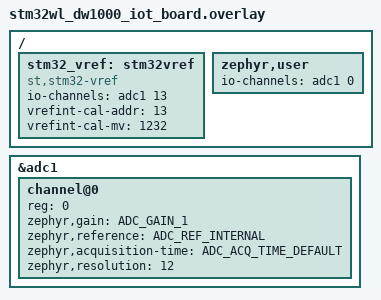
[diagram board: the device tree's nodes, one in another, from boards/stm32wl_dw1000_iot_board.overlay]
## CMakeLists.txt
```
cmake_minimum_required(VERSION 3.20.0)

find_package(Zephyr REQUIRED HINTS $ENV{ZEPHYR_BASE})
add_subdirectory(drivers)

project(stm32wle5_rtos_adc)

zephyr_include_directories(include)

FILE(GLOB app_sources src/*.c)
target_sources(app PRIVATE ${app_sources})
```

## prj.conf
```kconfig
# Debugger Support
CONFIG_UART_CONSOLE=y
CONFIG_CONSOLE=y

# Communication Bus Support
CONFIG_GPIO=y
CONFIG_SPI=y

# Hardware Support
CONFIG_SENSOR=y
CONFIG_ADC=y

# Power Management Support
CONFIG_PM=n
CONFIG_PM_DEVICE=n
CONFIG_PM_DEVICE_RUNTIME=n
CONFIG_PM_DEVICE_RUNTIME_EXCLUSIVE=n

# Flash Memory Support
CONFIG_EEPROM=y
CONFIG_FLASH=y
CONFIG_MPU_ALLOW_FLASH_WRITE=y
```

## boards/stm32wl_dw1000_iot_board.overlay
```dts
/*
 * Copyright (c) 2023
 * Regis Rousseau
 * Univ Lyon, INSA Lyon, Inria, CITI, EA3720
 * SPDX-License-Identifier: Apache-2.0
 */

/* VREF internal voltage monitoring */
/* internal voltage reference of STM32, IN13 - see datasheet pg 42/149 */
/* Vrefint = 1232mV max - see datasheet pg 78/149, table 36 */
/ {
	stm32_vref: stm32vref {
    	compatible = "st,stm32-vref";
		io-channels = <&adc1 13>;
		vrefint-cal-addr = <13>;
		vrefint-cal-mv = <1232>;
    	status = "okay";
	};
};

/* configuration of ADC for geophone sensor */
/* adjust channel number according to pinmux in board.dts */
/* PB13 ADC_GSONE -> ADC_IN0, see datasheet Pinout Config pg 57/149 */
/ {
	zephyr,user {		
		io-channels = <&adc1 0>;
	};
};

/* channel IN0 configuration */
&adc1 {
	#address-cells = <1>;
	#size-cells = <0>;
	channel@0 {
		reg = <0>;
		zephyr,gain = "ADC_GAIN_1";
		zephyr,reference = "ADC_REF_INTERNAL";
		zephyr,acquisition-time = <ADC_ACQ_TIME_DEFAULT>;
		zephyr,resolution = <12>;
	};
};
```

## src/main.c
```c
/*
 * Copyright (c) 2023
 * Regis Rousseau
 * Univ Lyon, INSA Lyon, Inria, CITI, EA3720
 * SPDX-License-Identifier: Apache-2.0
 */
 
#include "app_adc.h"
#include "app_vref.h"
#include "app_rom.h"


//  ======== interrupt sub-routine ===============================
void geo_work_handler(struct k_work *work_geo)
{
	const struct device *rom_dev = NULL;

	printk("ADC handler called\n");
	app_rom_handler(rom_dev);
}
K_WORK_DEFINE(geo_work, geo_work_handler);

void geo_timer_handler(struct k_timer *geo_dum)
{
	k_work_submit(&geo_work);
}
K_TIMER_DEFINE(geo_timer, geo_timer_handler, NULL);

//  ======== main ===============================================
int8_t main(void)
{
	const struct device *rom_dev = NULL;
	const struct device *vref_dev = NULL;
	uint16_t vref;

	// setup all devices
	app_rom_init(rom_dev);
	app_stm32_vref_init(vref_dev);

	printk("ADC STM32 Example\nBoard: %s\n", CONFIG_BOARD);

	// beginning of interrupt subroutine
//	k_timer_start(&geo_timer, K_NO_WAIT, K_MSEC(5000));
	vref_dev = DEVICE_DT_GET_ONE(st_stm32_vref);
	vref = app_stm32_get_vref(vref_dev);

	while(1) {
		uint16_t val = app_adc_get_val(vref);
		k_sleep(K_MSEC(1000)); // for the test
	}
	return 0;
}
```

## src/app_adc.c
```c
/*
 * Copyright (c) 2023
 * Regis Rousseau
 * Univ Lyon, INSA Lyon, Inria, CITI, EA3720
 * SPDX-License-Identifier: Apache-2.0
 */

#include "app_adc.h"
#include "app_vref.h"

//  ======== globals ============================================
uint16_t sp_buf;		

static const struct adc_dt_spec adc_channels[] = {
	DT_FOREACH_PROP_ELEM(DT_PATH(zephyr_user), io_channels, DT_SPEC_AND_COMMA)
};

struct adc_sequence adc_ch0_seq = {
	.buffer 		= &sp_buf,
	.buffer_size	= sizeof(sp_buf),
	.calibrate 		= true,
};

//  ======== app_adc_get_val ====================================
uint16_t app_adc_get_val(uint16_t val)
{
	int8_t err;
	uint16_t val_mv, buf;

	// getting STM32 ADC device at GPIO IN0 PB13
	for (size_t i = 0U; i < ARRAY_SIZE(adc_channels); i++) {
		if (!device_is_ready(adc_channels[i].dev)) {
			printk("ADC controller device %s not ready\n", adc_channels[i].dev->name);
		return 0;
		}
		
		// getting channel setup in devicetree
		err = adc_channel_setup_dt(&adc_channels[i]);
		if (err < 0) {
			printk("could not setup channel 0. error: %d\n", err);
			return 0;
		}
	}

	for (size_t i = 0U; i < ARRAY_SIZE(adc_channels); i++) {
		// initialization of channel and getting data
		(void)adc_sequence_init_dt(&adc_channels[i], &adc_ch0_seq);

		// getting value and printing numerical data
		// resolution 12 bits: 0 to 4095 (uint16)
		(void)adc_read(adc_channels[i].dev, &adc_ch0_seq);
		buf = (sp_buf*val)/4096;
		val_mv = (sp_buf*val)/3300;
		printk("buffer: %"PRIu16", adc num: %"PRIu16" - adc mv: %"PRIu16"\n", sp_buf, buf, val_mv);
	}
	return buf;
}
```

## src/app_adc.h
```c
/*
 * Copyright (c) 2023
 * Regis Rousseau
 * Univ Lyon, INSA Lyon, Inria, CITI, EA3720
 * SPDX-License-Identifier: Apache-2.0
 */

#ifndef APP_ADC_H
#define APP_ADC_H

//  ======== includes =============================================
#include <zephyr/kernel.h>
#include <zephyr/device.h>
#include <zephyr/drivers/adc.h>
#include <zephyr/drivers/sensor.h>

//  ======== defines ==============================================
#define DT_SPEC_AND_COMMA(node_id, prop, idx)   ADC_DT_SPEC_GET_BY_IDX(node_id, idx)

//  ======== prototypes ===========================================
uint16_t app_adc_get_val(uint16_t val);

#endif /* APP_ADC_H */
```

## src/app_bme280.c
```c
/*
 * Copyright (c) 2023
 * Regis Rousseau
 * Univ Lyon, INSA Lyon, Inria, CITI, EA3720
 * SPDX-License-Identifier: Apache-2.0
 */

 #include "app_bme280.h"
 #include "app_nvs.h"

int8_t app_bme280_init(const struct device *dev)
{
    dev = DEVICE_DT_GET_ANY(bosch_bme280);
    if (dev == NULL) {
        printk("error: no bme280 device found\n");
		return 0;
	}

    if (!device_is_ready(dev)) {
		printk("error: bme280 is not ready\n");
		return 0;
	}

    printk("found device \"%s\", getting bme280 data\n", dev->name);
    return 0;
}

int8_t app_bme280_handler(const struct device *dev)
{
    static struct nvs_fs fs;
    struct sensor_value temp;
    struct sensor_value hum;
    int8_t ret = 0;

    dev = DEVICE_DT_GET_ANY(bosch_bme280);

	ret = sensor_sample_fetch(dev);
    if (ret < 0 && ret != -EBADMSG) { 
	    printk("bme280 device sample is not up to date. error: %d\n", ret);
	    return 0;
    }

	ret = sensor_channel_get(dev, SENSOR_CHAN_AMBIENT_TEMP, &temp);
    if (ret < 0) {
        printk("can't read sensor channels. error: %d\n", ret);
	    return 0;
    }
    nvs_write(&fs, BME280_TEMP_ID, &temp, sizeof(temp));

	ret = sensor_channel_get(dev, SENSOR_CHAN_HUMIDITY, &hum);
    if (ret < 0) {
        printk("can't read sensor channels. error: %d\n");
	    return 0;
    }

    nvs_write(&fs, BME280_HUM_ID, &hum, sizeof(hum));
    printk("temp: %d.%03d; press: %d.%03d\n",temp.val1, temp.val2, hum.val1, hum.val2);

    return 0;
}
```

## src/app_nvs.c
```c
/*
 * Copyright (c) 2023
 * Regis Rousseau
 * Univ Lyon, INSA Lyon, Inria, CITI, EA3720
 * SPDX-License-Identifier: Apache-2.0
 */

#include "app_nvs.h"

int app_nvs_init(struct nvs_fs *fs)
{
	struct flash_pages_info info;
	int ret = 0;

	fs->flash_device = NVS_PARTITION_DEVICE;
	if (!device_is_ready(fs->flash_device)) {
		printk("flash device %s is not ready\n", fs->flash_device->name);
		return 0;
	}

	fs->offset = NVS_PARTITION_OFFSET;
	ret = flash_get_page_info_by_offs(fs->flash_device, fs->offset, &info);
	if (ret) {
		printk("unable to get page info. error: %d\n", ret);
		return 0;
	}

	fs->sector_size = info.size;
	if (!fs->sector_size || fs->sector_size % info.size) {
		printk("invalid sector size");
		return -EINVAL;
	}

	fs->sector_count = 2U;

	ret = nvs_mount(fs);
	if (ret) {
		printk("flash init failed. error: %d\n", ret);
		return 0;
	}
}
```

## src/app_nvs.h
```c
/*
 * Copyright (c) 2023
 * Regis Rousseau
 * Univ Lyon, INSA Lyon, Inria, CITI, EA3720
 * SPDX-License-Identifier: Apache-2.0
 */

#ifndef APP_NVS_H
#define APP_NVS_H

#include <zephyr/kernel.h>
#include <zephyr/device.h>

#include <zephyr/fs/nvs.h>
#include <zephyr/drivers/flash.h>
#include <zephyr/storage/flash_map.h>

#define NVS_PARTITION			storage_partition
#define NVS_PARTITION_DEVICE	FIXED_PARTITION_DEVICE(NVS_PARTITION)
#define NVS_PARTITION_OFFSET	FIXED_PARTITION_OFFSET(NVS_PARTITION)

#define TIMER_RTC_ID            1
#define STM32_VBAT_ID           2
#define BME280_TEMP_ID          3
#define BME280_HUM_ID           4

int app_nvs_init(struct nvs_fs *fs);

#endif /* APP_NVS_H */
```

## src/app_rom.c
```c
/*
 * Copyright (c) 2023
 * Regis Rousseau
 * Univ Lyon, INSA Lyon, Inria, CITI, EA3720
 * SPDX-License-Identifier: Apache-2.0
 */

#include "app_rom.h"

//  ======== globals ============================================
int8_t ind;		// index used by Interrupt Service Routine

//  ======== app_rom_init =========================================
int8_t app_rom_init(const struct device *dev)
{
	int8_t ret;
	ssize_t size, page;

	// getting eeprom device
	dev = DEVICE_DT_GET(DT_ALIAS(eeprom0));

    if (dev == NULL) {
		printk("no eeprom device found. error: %d\n", dev);
		return 0;
	}
	
	if (!device_is_ready(dev)) {
		printk("eeprom is not ready\n");
		return 0;
	} else {
        printk("- found device \"%s\", writing/reading data\n", dev->name);
    }

	// getting the size of eeprom in bytes
	size = eeprom_get_size(dev);
	printk("size of eeprom: %zu\n", size);

	// getting the total number of flash pages in bytes
	page = flash_get_page_count(dev);
	printk("number of pages: %zu\n", page);

	// erasing all page at @0x00
	ret  = flash_erase(dev, ROM_OFFSET, 1024*ROM_PAGE_SIZE);
	if (ret!=0) {
		printk("error erasing flash. error: %d\n", ret);
	} else {
		printk("erased all %zu pages\n", page);
	}
	
	// initialisation of isr index
	ind = 0;
	return 0;
}

//  ======== app_rom_write ========================================
int8_t app_rom_write(const struct device *dev, uint16_t data[])
{
	int8_t ret;
	
	// writing data in the first page of 2kbytes
	ret = flash_write(dev, ROM_OFFSET, &data, sizeof(data));

	if (ret!=0) {
		printk("error writing data. error: %d\n", ret);
	} else {
		printk("wrote %zu bytes to address 0x00\n", sizeof(data));
	}

	// printing data
	for (ind = 0; ind < ROM_MAX_RECORDS; ind++) {
		printk("wrt -> rom val: %"PRIu16"\n", data[ind]);
	}
	return 0;
}

//  ======== app_rom_read =========================================
int8_t app_rom_read(const struct device *dev)
{
	int8_t ret;
	uint16_t data[ROM_MAX_RECORDS];

	// reading the first page
	ret = flash_read(dev, ROM_OFFSET, &data, sizeof(data));
	if (ret) {
		printk("error reading data. error: %d\n", ret);
	} else {
		printk("read %zu bytes from address 0x00\n", sizeof(data));
	}

	// reading data
	for (ind = 0; ind < ROM_MAX_RECORDS; ind++) {
		printk("rd -> rom val: %"PRIu16"\n", data[ind]);
	}
	return 0;
}

//  ======== app_rom_handler =======================================
int8_t app_rom_handler(const struct device *dev)
{
	int8_t ret;
	uint16_t data[ROM_MAX_RECORDS];

	// getting eeprom device
	dev = DEVICE_DT_GET(DT_ALIAS(eeprom0));

	// putting n structures in fisrt page for this test
	while (ind < ROM_MAX_RECORDS) {
		data[ind] = app_adc_get_val();
		ind++;
	}

	// writing and reading stored data
	app_rom_write(dev, data);
	app_rom_read(dev);

	// cleaning data storage partition
	(void)flash_erase(dev, ROM_OFFSET, 1024*ROM_PAGE_SIZE);
	ind = 0;
	return 0;
}
```

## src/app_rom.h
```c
/*
 * Copyright (c) 2023
 * Regis Rousseau
 * Univ Lyon, INSA Lyon, Inria, CITI, EA3720
 * SPDX-License-Identifier: Apache-2.0
 */
 
#ifndef APP_ROM_H_
#define APP_ROM_H_

//  ======== includes =============================================
#include <zephyr/kernel.h>
#include <zephyr/device.h>
#include <zephyr/drivers/flash.h>
#include <zephyr/drivers/eeprom.h>

//  ======== defines ==============================================
#define ROM_OFFSET              0x00
#define ROM_PAGE_SIZE           512
#define ROM_MAX_RECORDS         3   // 1 structure: ID+value = 3 bytes
                                    // number of structures to store per page
                                            
//  ======== prototypes ===========================================
int8_t app_rom_init(const struct device *dev);
int8_t app_rom_write(const struct device *dev, uint16_t data[]);
int8_t app_rom_read(const struct device *dev);
int8_t app_rom_handler(const struct device *dev);

#endif /* APP_ROM_H_ */
```

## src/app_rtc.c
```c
/*
 * Copyright (c) 2023
 * Regis Rousseau
 * Univ Lyon, INSA Lyon, Inria, CITI, EA3720
 * SPDX-License-Identifier: Apache-2.0
 */

#include "app_rtc.h"

int8_t app_rtc_init(const struct device *dev)
{
    dev = DEVICE_DT_GET(TIMER);   // get sensor device

    if (dev == NULL) {
        printk("no timer device found. error: %d\n", dev);
		return 0;
	}
    if (!device_is_ready(dev)) {
		printk("timer is not ready. error: %d\n", dev);
		return 0;
	}
    return 0;
}

int8_t app_rtc_handler(const struct device *dev)
{
    int32_t ret = 0;

    time_t compile_timestamp = 11699437198; // timestamp local time GMT+1
    struct tm   ttm;
    //struct timespec time_now_ts;
    
    dev = DEVICE_DT_GET(TIMER);

    uint32_t *ticks = k_malloc(sizeof(uint32_t));
    memset(ticks, 0, sizeof(uint32_t));

    ret = counter_get_value(dev, ticks);

    if(ret < 0) {
            printk("counter get value failed.\n\r");
            return 0;
    }
    else {
        time_t time_now = compile_timestamp + *ticks + 3600;
        ttm = * gmtime(&time_now);
        printk("counter value: %d\n\r", *ticks);
        printk("current time: %02d:%02d:%02d\n\r", ttm.tm_hour, ttm.tm_min, ttm.tm_sec);
    }    
    return 0;
}
```

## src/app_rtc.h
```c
/*
 * Copyright (c) 2023
 * Regis Rousseau
 * Univ Lyon, INSA Lyon, Inria, CITI, EA3720
 * SPDX-License-Identifier: Apache-2.0
 */
#ifndef APP_RTC_H_
#define APP_RTC_H_

#include <zephyr/kernel.h>
#include <zephyr/device.h>
#include <zephyr/drivers/counter.h>
#include <zephyr/drivers/gpio.h>
#include <zephyr/posix/time.h>

#define TIMER DT_INST(0, st_stm32_rtc)

/* 1000 msec = 1 sec */
#define SLEEP_TIME_MS   10000

int8_t app_rtc_init(const struct device *dev);
int8_t app_rtc_handler(const struct device *dev);

#endif /* APP_RTC_H_ */
```

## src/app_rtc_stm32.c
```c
/*
 * Copyright (c) 2023
 * Regis Rousseau
 * Univ Lyon, INSA Lyon, Inria, CITI, EA3720
 * SPDX-License-Identifier: Apache-2.0
 */

#include "app_rtc_stm32.h"
#include "app_nvs.h"

int8_t app_rtc_stm32_init(const struct device *dev)
{
    dev = DEVICE_DT_GET(TIMER);   // get sensor device

    if (dev == NULL) {
        printk("no timer device found. error: %d\n", dev);
		return 0;
	}
    if (!device_is_ready(dev)) {
		printk("timer is not ready. error: %d\n", dev);
		return 0;
	}
    return 0;
}

int8_t app_rtc_stm32_handler(const struct device *dev)
{
    static struct nvs_fs fs;
    int32_t ret = 0;

    time_t compile_timestamp = 11699437198; // timestamp local time GMT+1
    struct tm   ttm;
    //struct timespec time_now_ts;
    
    dev = DEVICE_DT_GET(TIMER);

    uint32_t *ticks = k_malloc(sizeof(uint32_t));
    memset(ticks, 0, sizeof(uint32_t));

    ret = counter_get_value(dev, ticks);

    if(ret < 0) {
            printk("counter get value failed.\n\r");
            return 0;
    }
    else {
        time_t time_now = compile_timestamp + *ticks + 3600;
        ttm = * gmtime(&time_now);
        printk("counter value: %d\n\r", *ticks);
        printk("current time: %02d:%02d:%02d\n\r", ttm.tm_hour, ttm.tm_min, ttm.tm_sec);
    }
    //nvs_write(&fs, TIMER_RTC_ID , &ttm, sizeof(ttm));
    
    return 0;

}
```

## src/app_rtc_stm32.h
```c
/*
 * Copyright (c) 2023
 * Regis Rousseau
 * Univ Lyon, INSA Lyon, Inria, CITI, EA3720
 * SPDX-License-Identifier: Apache-2.0
 */
#ifndef APP_RTC_STM32_H_
#define APP_RTC_STM32_H_

#include <zephyr/kernel.h>
#include <zephyr/device.h>
#include <zephyr/logging/log.h>
#include <zephyr/types.h>
#include <zephyr/posix/time.h>
#include <zephyr/drivers/counter.h>

#include <string.h>

#define TIMER DT_INST(0, st_stm32_rtc)

/* 1000 msec = 1 sec */
#define SLEEP_TIME_MS   10000

int8_t app_rtc_stm32_init(const struct device *dev);
int8_t app_rtc_stm32_handler(const struct device *dev);

#endif /* APP_RTC_STM32_H_ */
```

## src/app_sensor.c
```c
/*
 * Copyright (c) 2023
 * Regis Rousseau
 * Univ Lyon, INSA Lyon, Inria, CITI, EA3720
 * SPDX-License-Identifier: Apache-2.0
 */

#include "app_sensor.h"

static uint16_t samp_buf[BUFFER_SIZE];

/* data of ADC io-channels specified in devicetree. */
static const struct adc_channel_cfg adc_chan0 = {
	.channel_id       = 0, // gets set during init
	.gain             = ADC_GAIN,
	.reference        = ADC_REFERENCE,
	.acquisition_time = ADC_ACQUISITION_TIME,
	.differential	  = 0,
};

struct adc_sequence sequence = {
		.options     = NULL,				// extra samples and callback
		.channels    = BIT(0),				// bit mask of channels to read
		.buffer = &samp_buf,
		.buffer_size = sizeof(samp_buf),	//buffer size in bytes, not number of samples
		.resolution  = ADC_RESOLUTION,		// desired resolution
		.oversampling = 0,					// don't oversample
		.calibrate = 0						// don't calibrate
	};
	
uint16_t app_adc_stm32_handler(void) {

	int err;
	uint16_t samp_val;

	(void)adc_sequence_init_dt(&adc_chan0, &sequence);

	err = adc_read(&adc_chan0, &sequence);
			if (err < 0) {
				printk("could not read (%d)\n", err);
			}
			if (err == 0) {
				samp_val = samp_buf[0];
			}
			return samp_val;
}
```
